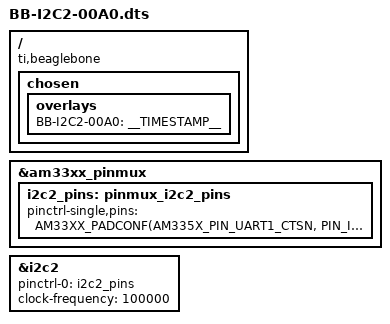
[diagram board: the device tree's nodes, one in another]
/*
 * Device Tree Overlay for BeagleBone Black I2C2
 * Enables I2C2 on pins P9.19 (SCL) and P9.20 (SDA)
 */
/dts-v1/;
/plugin/;

#include <dt-bindings/board/am335x-bbw-bbb-base.h>
#include <dt-bindings/pinctrl/am33xx.h>

/ {
    compatible = "ti,beaglebone", "ti,beaglebone-black";

    /* This overlay will only work with specific hardware */
    fragment@0 {
        target-path = "/";
        __overlay__ {
            chosen {
                overlays {
                    BB-I2C2-00A0 = __TIMESTAMP__;
                };
            };
        };
    };

    /* Enable I2C2 pins */
    fragment@1 {
        target = <&am33xx_pinmux>;
        __overlay__ {
            i2c2_pins: pinmux_i2c2_pins {
                pinctrl-single,pins = <
                    AM33XX_PADCONF(AM335X_PIN_UART1_CTSN, PIN_INPUT_PULLUP, MUX_MODE3)    /* uart1_ctsn.i2c2_sda */
                    AM33XX_PADCONF(AM335X_PIN_UART1_RTSN, PIN_INPUT_PULLUP, MUX_MODE3)    /* uart1_rtsn.i2c2_scl */
                >;
            };
        };
    };

    /* Enable the I2C2 controller */
    fragment@2 {
        target = <&i2c2>;
        __overlay__ {
            status = "okay";
            pinctrl-names = "default";
            pinctrl-0 = <&i2c2_pins>;

            /* Set the clock frequency for I2C2 */
            clock-frequency = <100000>;

            /* This is where you would add I2C device nodes if needed */
            /* For example:
            my_i2c_device: my_device@xx {
                compatible = "vendor,device";
                reg = <0xXX>;
            };
            */
        };
    };
};
